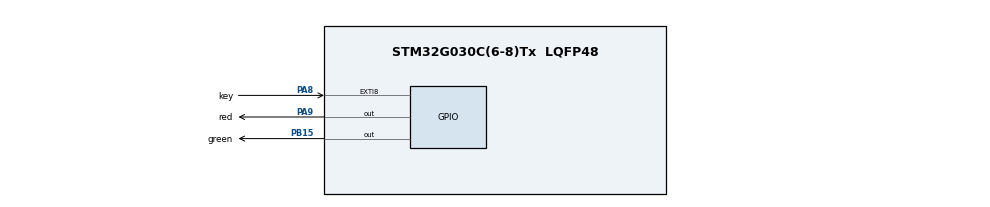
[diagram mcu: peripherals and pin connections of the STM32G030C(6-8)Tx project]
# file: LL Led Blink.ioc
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Mcu.Family=STM32G0
Mcu.Name=STM32G030C(6-8)Tx
Mcu.Package=LQFP48
NVIC.EXTI4_15_IRQn=true\:0\:0\:false\:false\:true\:true\:true\:true
PA13.Mode=Serial_Wire
PA13.Signal=SYS_SWDIO
PA14-BOOT0.Mode=Serial_Wire
PA14-BOOT0.Signal=SYS_SWCLK
PA8.GPIO_Label=key
PA8.GPIO_ModeDefaultEXTI=GPIO_MODE_IT_FALLING
PA8.GPIO_PuPd=GPIO_PULLUP
PA8.Signal=GPXTI8
PA9.GPIO_Label=red
PA9.PinState=GPIO_PIN_SET
PA9.Signal=GPIO_Output
PB15.GPIO_Label=green
PB15.PinState=GPIO_PIN_RESET
PB15.Signal=GPIO_Output
PF0-OSC_IN\ (PF0).Mode=HSE-External-Oscillator
PF0-OSC_IN\ (PF0).Signal=RCC_OSC_IN
PF1-OSC_OUT\ (PF1).Mode=HSE-External-Oscillator
PF1-OSC_OUT\ (PF1).Signal=RCC_OSC_OUT
ProjectManager.HeapSize=0x200
ProjectManager.StackSize=0x400
ProjectManager.TargetToolchain=MDK-ARM V5.32
RCC.ADCFreq_Value=64000000
RCC.AHBFreq_Value=64000000
RCC.CortexFreq_Value=64000000
RCC.EXTERNAL_CLOCK_VALUE=12288000
RCC.HCLKFreq_Value=64000000
RCC.HSE_VALUE=8000000
RCC.HSI_VALUE=16000000
RCC.LSE_VALUE=32768
RCC.PLLN=16
RCC.PLLSourceVirtual=RCC_PLLSOURCE_HSE
RCC.SYSCLKFreq_VALUE=64000000
RCC.SYSCLKSource=RCC_SYSCLKSOURCE_PLLCLK
RCC.VCOOutputFreq_Value=128000000
board=custom

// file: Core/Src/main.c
/* USER CODE BEGIN Header */
/**
  ******************************************************************************
  * @file           : main.c
  * @brief          : Main program body
  ******************************************************************************
  * @attention
  *
  * Copyright (c) 2023 STMicroelectronics.
  * All rights reserved.
  *
  * This software is licensed under terms that can be found in the LICENSE file
  * in the root directory of this software component.
  * If no LICENSE file comes with this software, it is provided AS-IS.
  *
  ******************************************************************************
  */
/* USER CODE END Header */
#include "main.h"

void SystemClock_Config(void);
static void MX_GPIO_Init(void);

int main(void)
{

  /* MCU Configuration--------------------------------------------------------*/

  /* Reset of all peripherals, Initializes the Flash interface and the Systick. */
  LL_APB2_GRP1_EnableClock(LL_APB2_GRP1_PERIPH_SYSCFG);
  LL_APB1_GRP1_EnableClock(LL_APB1_GRP1_PERIPH_PWR);

  /* SysTick_IRQn interrupt configuration */
  NVIC_SetPriority(SysTick_IRQn, 3);

  /* Configure the system clock */
  SystemClock_Config();

  /* Initialize all configured peripherals */
  MX_GPIO_Init();

  /* Infinite loop */
  /* USER CODE BEGIN WHILE */
  while (1)
  {
		LL_GPIO_TogglePin(red_GPIO_Port,red_Pin);
		LL_mDelay(1000);

//		}
    /* USER CODE END WHILE */

  }
}

void SystemClock_Config(void)
{
  LL_FLASH_SetLatency(LL_FLASH_LATENCY_2);
  while(LL_FLASH_GetLatency() != LL_FLASH_LATENCY_2)
  {
  }

  /* HSE configuration and activation */
  LL_RCC_HSE_Enable();
  while(LL_RCC_HSE_IsReady() != 1)
  {
  }

  /* Main PLL configuration and activation */
  LL_RCC_PLL_ConfigDomain_SYS(LL_RCC_PLLSOURCE_HSE, LL_RCC_PLLM_DIV_1, 16, LL_RCC_PLLR_DIV_2);
  LL_RCC_PLL_Enable();
  LL_RCC_PLL_EnableDomain_SYS();
  while(LL_RCC_PLL_IsReady() != 1)
  {
  }

  /* Set AHB prescaler*/
  LL_RCC_SetAHBPrescaler(LL_RCC_SYSCLK_DIV_1);

  /* Sysclk activation on the main PLL */
  LL_RCC_SetSysClkSource(LL_RCC_SYS_CLKSOURCE_PLL);
  while(LL_RCC_GetSysClkSource() != LL_RCC_SYS_CLKSOURCE_STATUS_PLL)
  {
  }

  /* Set APB1 prescaler*/
  LL_RCC_SetAPB1Prescaler(LL_RCC_APB1_DIV_1);

  LL_Init1msTick(64000000);

  /* Update CMSIS variable (which can be updated also through SystemCoreClockUpdate function) */
  LL_SetSystemCoreClock(64000000);
}

static void MX_GPIO_Init(void)
{
  LL_EXTI_InitTypeDef EXTI_InitStruct = {0};
  LL_GPIO_InitTypeDef GPIO_InitStruct = {0};

  /* GPIO Ports Clock Enable */
  LL_IOP_GRP1_EnableClock(LL_IOP_GRP1_PERIPH_GPIOF);
  LL_IOP_GRP1_EnableClock(LL_IOP_GRP1_PERIPH_GPIOB);
  LL_IOP_GRP1_EnableClock(LL_IOP_GRP1_PERIPH_GPIOA);

  /**/
  LL_GPIO_ResetOutputPin(green_GPIO_Port, green_Pin);

  /**/
  LL_GPIO_SetOutputPin(red_GPIO_Port, red_Pin);

  /**/
  GPIO_InitStruct.Pin = green_Pin;
  GPIO_InitStruct.Mode = LL_GPIO_MODE_OUTPUT;
  GPIO_InitStruct.Speed = LL_GPIO_SPEED_FREQ_LOW;
  GPIO_InitStruct.OutputType = LL_GPIO_OUTPUT_PUSHPULL;
  GPIO_InitStruct.Pull = LL_GPIO_PULL_NO;
  LL_GPIO_Init(green_GPIO_Port, &GPIO_InitStruct);

  /**/
  GPIO_InitStruct.Pin = red_Pin;
  GPIO_InitStruct.Mode = LL_GPIO_MODE_OUTPUT;
  GPIO_InitStruct.Speed = LL_GPIO_SPEED_FREQ_LOW;
  GPIO_InitStruct.OutputType = LL_GPIO_OUTPUT_PUSHPULL;
  GPIO_InitStruct.Pull = LL_GPIO_PULL_NO;
  LL_GPIO_Init(red_GPIO_Port, &GPIO_InitStruct);

  /**/
  LL_EXTI_SetEXTISource(LL_EXTI_CONFIG_PORTA, LL_EXTI_CONFIG_LINE8);

  /**/
  EXTI_InitStruct.Line_0_31 = LL_EXTI_LINE_8;
  EXTI_InitStruct.LineCommand = ENABLE;
  EXTI_InitStruct.Mode = LL_EXTI_MODE_IT;
  EXTI_InitStruct.Trigger = LL_EXTI_TRIGGER_FALLING;
  LL_EXTI_Init(&EXTI_InitStruct);

  /**/
  LL_GPIO_SetPinPull(key_GPIO_Port, key_Pin, LL_GPIO_PULL_UP);

  /**/
  LL_GPIO_SetPinMode(key_GPIO_Port, key_Pin, LL_GPIO_MODE_INPUT);

  /* EXTI interrupt init*/
  NVIC_SetPriority(EXTI4_15_IRQn, 0);
  NVIC_EnableIRQ(EXTI4_15_IRQn);

}

void Error_Handler(void)
{
  __disable_irq();
  while (1)
  {
  }
}
